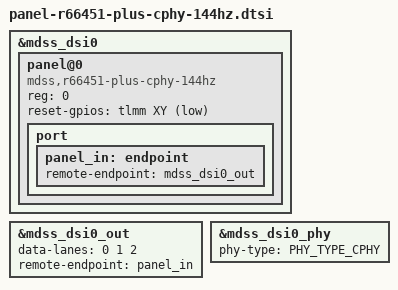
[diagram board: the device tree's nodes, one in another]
#include <dt-bindings/phy/phy.h>

&mdss_dsi0 {
	panel@0 {
		compatible = "mdss,r66451-plus-cphy-144hz";
		reg = <0>;

		reset-gpios = <&tlmm XY GPIO_ACTIVE_LOW>;

		port {
			panel_in: endpoint {
				remote-endpoint = <&mdss_dsi0_out>;
			};
		};
	};
};

&mdss_dsi0_out {
	data-lanes = <0 1 2>;
	remote-endpoint = <&panel_in>;
};

&mdss_dsi0_phy {
    phy-type = <PHY_TYPE_CPHY>;
};
